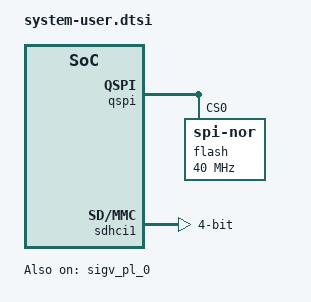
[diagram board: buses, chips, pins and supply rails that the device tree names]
/include/ "system-conf.dtsi"
/ {
	aliases {
		mmc0 = &sdhci1;
	};
};

&qspi {
	flash@0 {
		compatible = "jedec,spi-nor";
		reg = <0>;
		spi-tx-bus-width = <4>;
		spi-rx-bus-width = <4>;
		spi-max-frequency = <40000000>;
		#address-cells = <1>;
		#size-cells = <1>;
	};
};

&sdhci1 {
	bus-width = <4>;
	disable-wp;
	no-1-8-v;
	broken-cd;
	status = "okay";
};

&sigv_pl_0 {
	compatible = "generic-uio";
	status = "okay";
};

&axi_bram_ctrl_message {
	compatible = "generic-uio";
	status = "okay";
};

&axi_bram_ctrl_job {
	compatible = "generic-uio";
	status = "okay";
};
